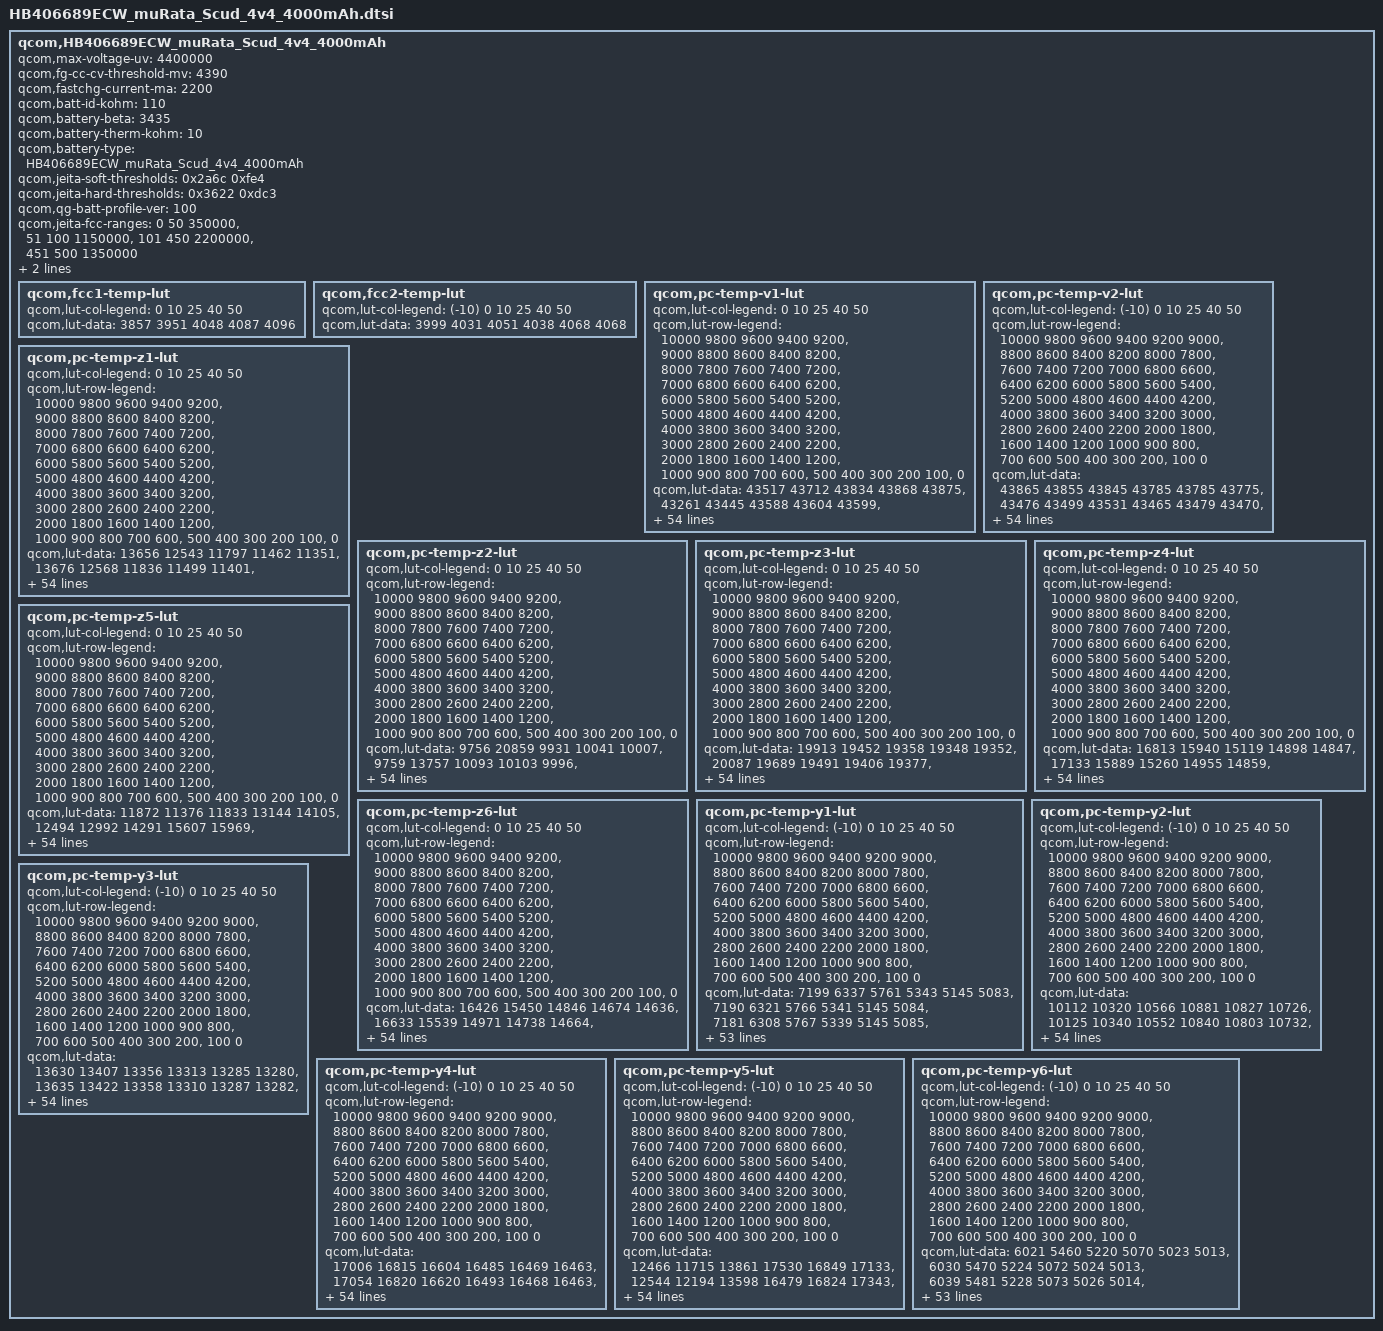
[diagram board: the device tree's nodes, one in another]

qcom,HB406689ECW_muRata_Scud_4v4_4000mAh {
    /* 3463304_Huawei_BangkokScud_4000mAh_averaged_MasterSlave_Jul12th2018 */
    qcom,max-voltage-uv = <4400000>;
    qcom,fg-cc-cv-threshold-mv = <4390>;
    qcom,fastchg-current-ma = <2200>;
    qcom,batt-id-kohm = <110>;
    qcom,battery-beta = <3435>;
    qcom,battery-therm-kohm = <10>;
    qcom,battery-type = "HB406689ECW_muRata_Scud_4v4_4000mAh";
    qcom,jeita-soft-thresholds = <0x2a6c 0xfe4>;
    qcom,jeita-hard-thresholds = <0x3622 0xdc3>;
    qcom,qg-batt-profile-ver = <100>;
    qcom,jeita-fcc-ranges = <0   50  350000>,
                            <51  100  1150000>,
			    <101  450  2200000>,
			    <451  500  1350000>;
	qcom,jeita-fv-ranges = <0   450  4400000>,
				<451 500  4100000>;

	qcom,fcc1-temp-lut {
		qcom,lut-col-legend = <0 10 25 40 50>;
		qcom,lut-data = <3857 3951 4048 4087 4096>;
	};

	qcom,fcc2-temp-lut {
		qcom,lut-col-legend = <(-10) 0 10 25 40 50>;
		qcom,lut-data = <3999 4031 4051 4038 4068 4068>;
	};

	qcom,pc-temp-v1-lut {
		qcom,lut-col-legend = <0 10 25 40 50>;
		qcom,lut-row-legend = <10000 9800 9600 9400 9200>,
			<9000 8800 8600 8400 8200>,
			<8000 7800 7600 7400 7200>,
			<7000 6800 6600 6400 6200>,
			<6000 5800 5600 5400 5200>,
			<5000 4800 4600 4400 4200>,
			<4000 3800 3600 3400 3200>,
			<3000 2800 2600 2400 2200>,
			<2000 1800 1600 1400 1200>,
			<1000 900 800 700 600>,
			<500 400 300 200 100>,
			<0>;
		qcom,lut-data = <43517 43712 43834 43868 43875>,
			<43261 43445 43588 43604 43599>,
			<43008 43186 43334 43355 43344>,
			<42759 42934 43079 43107 43099>,
			<42515 42689 42831 42860 42855>,
			<42275 42445 42586 42613 42614>,
			<42041 42204 42343 42368 42376>,
			<41811 41967 42101 42127 42137>,
			<41587 41738 41863 41888 41899>,
			<41369 41514 41629 41655 41664>,
			<41157 41296 41400 41427 41434>,
			<40951 41082 41180 41204 41209>,
			<40753 40874 40965 40986 40990>,
			<40564 40676 40759 40775 40779>,
			<40381 40485 40559 40571 40576>,
			<40204 40303 40367 40376 40382>,
			<40035 40132 40186 40191 40197>,
			<39873 39967 40014 40018 40019>,
			<39718 39806 39847 39851 39848>,
			<39570 39650 39693 39692 39687>,
			<39427 39492 39535 39536 39532>,
			<39289 39335 39338 39355 39355>,
			<39161 39179 39094 39118 39131>,
			<39038 39018 38894 38904 38919>,
			<38922 38855 38752 38763 38769>,
			<38810 38708 38637 38650 38647>,
			<38704 38571 38540 38542 38534>,
			<38607 38457 38459 38439 38431>,
			<38515 38379 38383 38346 38337>,
			<38433 38317 38309 38262 38251>,
			<38367 38265 38241 38187 38172>,
			<38309 38218 38178 38117 38101>,
			<38258 38176 38122 38054 38036>,
			<38216 38135 38069 37996 37975>,
			<38177 38096 38022 37947 37919>,
			<38135 38056 37977 37900 37864>,
			<38090 38017 37931 37847 37801>,
			<38042 37973 37884 37791 37735>,
			<37991 37907 37820 37721 37656>,
			<37934 37811 37723 37626 37560>,
			<37849 37701 37608 37513 37450>,
			<37703 37575 37486 37391 37328>,
			<37536 37429 37348 37252 37189>,
			<37353 37246 37172 37083 37019>,
			<37166 37097 37003 36920 36860>,
			<37019 36974 36879 36799 36743>,
			<36958 36920 36835 36756 36697>,
			<36896 36870 36786 36710 36649>,
			<36814 36805 36720 36640 36574>,
			<36639 36658 36540 36418 36337>,
			<36236 36296 36161 36032 35949>,
			<35698 35805 35668 35540 35457>,
			<34998 35169 35040 34912 34834>,
			<34001 34313 34194 34066 33987>,
			<32357 32982 32888 32746 32668>,
			<30000 30000 30000 30000 30000>;
	};

	qcom,pc-temp-v2-lut {
		qcom,lut-col-legend = <(-10) 0 10 25 40 50>;
		qcom,lut-row-legend = <10000 9800 9600 9400 9200 9000>,
			<8800 8600 8400 8200 8000 7800>,
			<7600 7400 7200 7000 6800 6600>,
			<6400 6200 6000 5800 5600 5400>,
			<5200 5000 4800 4600 4400 4200>,
			<4000 3800 3600 3400 3200 3000>,
			<2800 2600 2400 2200 2000 1800>,
			<1600 1400 1200 1000 900 800>,
			<700 600 500 400 300 200>,
			<100 0>;
		qcom,lut-data = <43865 43855 43845 43785 43785 43775>,
			<43476 43499 43531 43465 43479 43470>,
			<43121 43176 43238 43168 43191 43183>,
			<42806 42889 42966 42896 42926 42919>,
			<42527 42637 42717 42649 42682 42675>,
			<42259 42392 42473 42408 42442 42435>,
			<41994 42146 42227 42167 42199 42194>,
			<41734 41903 41985 41928 41960 41956>,
			<41476 41659 41749 41694 41725 41721>,
			<41219 41415 41518 41462 41495 41489>,
			<40970 41170 41291 41235 41268 41262>,
			<40733 40922 41069 41013 41046 41040>,
			<40504 40676 40848 40797 40828 40822>,
			<40272 40437 40620 40591 40620 40615>,
			<40039 40204 40388 40393 40417 40414>,
			<39816 39982 40159 40202 40223 40220>,
			<39613 39773 39930 40024 40036 40034>,
			<39420 39574 39710 39845 39855 39854>,
			<39234 39386 39507 39646 39676 39682>,
			<39055 39206 39314 39432 39500 39514>,
			<38887 39036 39135 39228 39309 39328>,
			<38729 38873 38968 39034 39090 39107>,
			<38581 38721 38814 38856 38886 38899>,
			<38439 38581 38674 38702 38725 38734>,
			<38303 38453 38546 38565 38587 38591>,
			<38178 38331 38426 38445 38464 38466>,
			<38065 38212 38315 38340 38356 38356>,
			<37961 38102 38211 38245 38259 38257>,
			<37868 38002 38115 38154 38170 38165>,
			<37784 37909 38024 38068 38089 38080>,
			<37705 37830 37942 37992 38016 38005>,
			<37628 37763 37865 37923 37949 37938>,
			<37553 37705 37796 37860 37882 37870>,
			<37478 37649 37737 37803 37816 37803>,
			<37403 37599 37684 37750 37747 37732>,
			<37327 37546 37633 37687 37661 37636>,
			<37252 37490 37584 37612 37559 37512>,
			<37175 37430 37529 37531 37460 37401>,
			<37098 37367 37458 37448 37375 37315>,
			<37021 37298 37374 37362 37291 37234>,
			<36941 37203 37276 37264 37199 37145>,
			<36856 37053 37156 37152 37099 37049>,
			<36764 36883 37017 37024 36975 36926>,
			<36662 36698 36850 36874 36830 36783>,
			<36535 36552 36656 36713 36694 36650>,
			<36376 36399 36516 36617 36620 36574>,
			<36267 36317 36454 36572 36576 36531>,
			<36146 36230 36390 36516 36511 36468>,
			<35993 36117 36300 36426 36386 36341>,
			<35783 35927 36131 36225 36088 36041>,
			<35457 35533 35770 35820 35626 35582>,
			<34913 34925 35206 35276 35042 35002>,
			<34065 34128 34462 34589 34284 34252>,
			<32953 32886 33489 33660 33238 33230>,
			<31547 31082 31993 32192 31519 31589>,
			<29383 26587 28489 28493 26939 26874>;
	};

	qcom,pc-temp-z1-lut {
		qcom,lut-col-legend = <0 10 25 40 50>;
		qcom,lut-row-legend = <10000 9800 9600 9400 9200>,
			<9000 8800 8600 8400 8200>,
			<8000 7800 7600 7400 7200>,
			<7000 6800 6600 6400 6200>,
			<6000 5800 5600 5400 5200>,
			<5000 4800 4600 4400 4200>,
			<4000 3800 3600 3400 3200>,
			<3000 2800 2600 2400 2200>,
			<2000 1800 1600 1400 1200>,
			<1000 900 800 700 600>,
			<500 400 300 200 100>,
			<0>;
		qcom,lut-data = <13656 12543 11797 11462 11351>,
			<13676 12568 11836 11499 11401>,
			<13687 12585 11842 11504 11406>,
			<13699 12596 11844 11507 11408>,
			<13701 12605 11842 11507 11409>,
			<13707 12602 11837 11507 11410>,
			<13709 12592 11834 11507 11411>,
			<13692 12584 11832 11508 11412>,
			<13667 12582 11831 11509 11415>,
			<13661 12578 11832 11510 11416>,
			<13668 12576 11835 11511 11417>,
			<13672 12576 11837 11513 11418>,
			<13650 12575 11840 11514 11420>,
			<13610 12567 11843 11516 11422>,
			<13587 12556 11845 11519 11424>,
			<13576 12555 11849 11521 11427>,
			<13569 12565 11852 11524 11430>,
			<13564 12573 11857 11527 11433>,
			<13562 12574 11862 11531 11436>,
			<13559 12575 11870 11534 11439>,
			<13547 12577 11877 11538 11441>,
			<13530 12580 11881 11542 11444>,
			<13520 12584 11883 11547 11447>,
			<13512 12590 11885 11552 11451>,
			<13504 12596 11891 11556 11454>,
			<13496 12600 11897 11559 11459>,
			<13488 12602 11905 11564 11463>,
			<13482 12603 11913 11571 11468>,
			<13476 12604 11919 11578 11472>,
			<13472 12606 11923 11583 11477>,
			<13473 12608 11927 11587 11481>,
			<13477 12613 11932 11592 11485>,
			<13481 12618 11938 11598 11489>,
			<13492 12622 11944 11603 11493>,
			<13505 12627 11951 11610 11498>,
			<13510 12633 11958 11616 11502>,
			<13513 12640 11966 11622 11507>,
			<13519 12650 11975 11627 11511>,
			<13539 12661 11983 11632 11516>,
			<13574 12674 11993 11637 11521>,
			<13605 12688 12003 11643 11526>,
			<13640 12701 12013 11649 11530>,
			<13659 12717 12024 11656 11534>,
			<13668 12750 12036 11664 11538>,
			<13673 12754 12056 11674 11544>,
			<13673 12763 12061 11681 11550>,
			<13666 12783 12063 11682 11551>,
			<13658 12745 12066 11688 11554>,
			<13667 12744 12070 11696 11561>,
			<13711 12765 12086 11707 11567>,
			<13725 12796 12088 11717 11575>,
			<13715 12824 12115 11725 11585>,
			<13735 12831 12126 11740 11598>,
			<13790 12854 12160 11759 11616>,
			<13790 12854 12160 11759 11616>,
			<13790 12854 12160 11759 11616>;
	};

	qcom,pc-temp-z2-lut {
		qcom,lut-col-legend = <0 10 25 40 50>;
		qcom,lut-row-legend = <10000 9800 9600 9400 9200>,
			<9000 8800 8600 8400 8200>,
			<8000 7800 7600 7400 7200>,
			<7000 6800 6600 6400 6200>,
			<6000 5800 5600 5400 5200>,
			<5000 4800 4600 4400 4200>,
			<4000 3800 3600 3400 3200>,
			<3000 2800 2600 2400 2200>,
			<2000 1800 1600 1400 1200>,
			<1000 900 800 700 600>,
			<500 400 300 200 100>,
			<0>;
		qcom,lut-data = <9756 20859 9931 10041 10007>,
			<9759 13757 10093 10103 9996>,
			<9793 9989 10151 10193 10054>,
			<9834 9931 10173 10244 10136>,
			<9851 9930 10164 10252 10150>,
			<9859 9929 10143 10241 10064>,
			<9867 9930 10131 10233 9994>,
			<9874 9932 10121 10235 10003>,
			<9881 9934 10116 10238 10021>,
			<9888 9936 10122 10229 10025>,
			<9897 9938 10134 10201 10021>,
			<9905 9940 10136 10187 10019>,
			<9913 9942 10131 10197 10032>,
			<9921 9941 10129 10210 10048>,
			<9928 9939 10133 10212 10050>,
			<9935 9939 10141 10208 10048>,
			<9939 9943 10149 10198 10047>,
			<9941 9949 10157 10139 10057>,
			<9940 9955 10165 10081 10070>,
			<9940 9964 10172 10076 10079>,
			<9940 9976 10180 10075 10087>,
			<9940 9993 10208 10086 10095>,
			<9941 10013 10280 10205 10109>,
			<9947 10033 10314 10304 10121>,
			<9955 10056 10268 10252 10125>,
			<9964 10072 10212 10147 10129>,
			<9975 10083 10209 10137 10124>,
			<9986 10090 10218 10235 10093>,
			<9998 10089 10222 10302 10061>,
			<10009 10085 10220 10276 10042>,
			<10013 10081 10217 10230 10027>,
			<10017 10075 10208 10202 10018>,
			<10018 10070 10192 10178 10010>,
			<10017 10069 10179 10159 10007>,
			<10016 10067 10168 10130 10018>,
			<10017 10067 10160 10102 10039>,
			<10021 10067 10157 10101 10062>,
			<10024 10068 10156 10115 10094>,
			<9871 10070 10157 10120 10115>,
			<9596 10078 10174 10120 10129>,
			<9512 10086 10190 10120 10138>,
			<9509 10090 10188 10122 10132>,
			<9505 10097 10184 10126 10117>,
			<9491 10115 10191 10144 10109>,
			<9550 10032 10225 10159 10109>,
			<9553 9967 10257 10157 10132>,
			<9525 9960 10247 10160 10119>,
			<9505 9958 10242 10162 10132>,
			<9494 9950 10242 10195 10167>,
			<9468 9940 10312 10173 10097>,
			<9475 9927 10273 10113 10010>,
			<9423 9863 10233 10047 9972>,
			<9360 9783 10201 10012 9935>,
			<9300 9664 10143 9963 9876>,
			<9300 9664 10143 9963 9876>,
			<9300 9664 10143 9963 9876>;
	};

	qcom,pc-temp-z3-lut {
		qcom,lut-col-legend = <0 10 25 40 50>;
		qcom,lut-row-legend = <10000 9800 9600 9400 9200>,
			<9000 8800 8600 8400 8200>,
			<8000 7800 7600 7400 7200>,
			<7000 6800 6600 6400 6200>,
			<6000 5800 5600 5400 5200>,
			<5000 4800 4600 4400 4200>,
			<4000 3800 3600 3400 3200>,
			<3000 2800 2600 2400 2200>,
			<2000 1800 1600 1400 1200>,
			<1000 900 800 700 600>,
			<500 400 300 200 100>,
			<0>;
		qcom,lut-data = <19913 19452 19358 19348 19352>,
			<20087 19689 19491 19406 19377>,
			<20148 19819 19537 19422 19398>,
			<20178 19850 19560 19433 19406>,
			<20177 19867 19562 19440 19408>,
			<20158 19875 19563 19447 19406>,
			<20138 19880 19563 19449 19404>,
			<20122 19882 19561 19447 19401>,
			<20108 19876 19558 19441 19398>,
			<20097 19863 19553 19435 19396>,
			<20088 19855 19544 19426 19394>,
			<20080 19851 19536 19421 19393>,
			<20070 19847 19528 19418 19391>,
			<20061 19842 19521 19417 19389>,
			<20060 19835 19518 19415 19386>,
			<20081 19824 19516 19413 19382>,
			<20113 19801 19513 19409 19379>,
			<20140 19780 19509 19402 19377>,
			<20167 19769 19505 19395 19376>,
			<20188 19760 19501 19392 19373>,
			<20202 19758 19498 19391 19371>,
			<20212 19761 19505 19392 19370>,
			<20213 19764 19531 19403 19374>,
			<20208 19772 19545 19412 19377>,
			<20202 19790 19533 19404 19378>,
			<20198 19799 19515 19389 19378>,
			<20194 19803 19507 19388 19381>,
			<20189 19805 19501 19405 19391>,
			<20180 19802 19499 19419 19398>,
			<20169 19792 19504 19422 19397>,
			<20158 19783 19512 19424 19395>,
			<20146 19775 19517 19424 19393>,
			<20134 19768 19521 19422 19389>,
			<20120 19764 19523 19419 19384>,
			<20106 19762 19522 19413 19378>,
			<20091 19759 19520 19406 19373>,
			<20078 19753 19516 19400 19369>,
			<20055 19745 19509 19395 19366>,
			<19876 19739 19503 19391 19365>,
			<19580 19732 19499 19389 19365>,
			<19478 19725 19496 19387 19365>,
			<19467 19719 19492 19388 19365>,
			<19449 19709 19489 19389 19365>,
			<19414 19690 19485 19386 19367>,
			<19404 19498 19472 19380 19365>,
			<19400 19371 19456 19378 19353>,
			<19392 19360 19445 19372 19351>,
			<19389 19337 19446 19369 19350>,
			<19389 19334 19450 19368 19348>,
			<19392 19349 19439 19386 19366>,
			<19417 19369 19468 19401 19376>,
			<19444 19369 19480 19404 19379>,
			<19471 19393 19489 19409 19382>,
			<19514 19399 19497 19414 19392>,
			<19514 19399 19497 19414 19392>,
			<19514 19399 19497 19414 19392>;
	};

	qcom,pc-temp-z4-lut {
		qcom,lut-col-legend = <0 10 25 40 50>;
		qcom,lut-row-legend = <10000 9800 9600 9400 9200>,
			<9000 8800 8600 8400 8200>,
			<8000 7800 7600 7400 7200>,
			<7000 6800 6600 6400 6200>,
			<6000 5800 5600 5400 5200>,
			<5000 4800 4600 4400 4200>,
			<4000 3800 3600 3400 3200>,
			<3000 2800 2600 2400 2200>,
			<2000 1800 1600 1400 1200>,
			<1000 900 800 700 600>,
			<500 400 300 200 100>,
			<0>;
		qcom,lut-data = <16813 15940 15119 14898 14847>,
			<17133 15889 15260 14955 14859>,
			<16952 15808 15187 14943 14867>,
			<16686 15672 15098 14894 14838>,
			<16496 15512 15037 14857 14815>,
			<16330 15398 14984 14829 14797>,
			<16189 15309 14942 14805 14781>,
			<16071 15237 14908 14781 14765>,
			<15971 15180 14880 14763 14750>,
			<15889 15134 14851 14758 14743>,
			<15820 15090 14827 14757 14739>,
			<15761 15048 14816 14755 14736>,
			<15710 15009 14811 14750 14732>,
			<15665 14972 14806 14744 14728>,
			<15611 14939 14798 14738 14724>,
			<15539 14918 14787 14733 14720>,
			<15460 14904 14778 14729 14716>,
			<15384 14893 14769 14727 14711>,
			<15306 14882 14761 14725 14705>,
			<15241 14872 14751 14720 14700>,
			<15191 14862 14743 14714 14696>,
			<15150 14851 14749 14716 14699>,
			<15118 14845 14782 14759 14744>,
			<15093 14847 14813 14801 14786>,
			<15072 14855 14839 14811 14786>,
			<15052 14867 14858 14817 14780>,
			<15035 14887 14858 14814 14770>,
			<15023 14903 14851 14785 14749>,
			<15016 14904 14841 14756 14730>,
			<15011 14902 14824 14740 14719>,
			<15005 14899 14805 14726 14710>,
			<15001 14891 14788 14716 14702>,
			<14995 14881 14771 14708 14694>,
			<14988 14869 14757 14703 14688>,
			<14977 14856 14747 14699 14685>,
			<14963 14841 14739 14698 14682>,
			<14941 14826 14735 14697 14682>,
			<14928 14812 14733 14698 14684>,
			<15085 14804 14733 14700 14685>,
			<15368 14798 14739 14706 14688>,
			<15448 14791 14745 14712 14689>,
			<15423 14778 14738 14707 14685>,
			<15393 14767 14725 14696 14678>,
			<15363 14762 14721 14699 14679>,
			<15186 14875 14708 14695 14677>,
			<15148 14965 14683 14670 14664>,
			<15152 14971 14682 14665 14656>,
			<15152 14988 14670 14655 14643>,
			<15141 14982 14664 14653 14642>,
			<15136 14968 14693 14663 14657>,
			<15140 14975 14684 14667 14665>,
			<15166 14997 14685 14672 14671>,
			<15180 14995 14687 14677 14675>,
			<15231 15027 14696 14682 14673>,
			<15231 15027 14696 14682 14673>,
			<15231 15027 14696 14682 14673>;
	};

	qcom,pc-temp-z5-lut {
		qcom,lut-col-legend = <0 10 25 40 50>;
		qcom,lut-row-legend = <10000 9800 9600 9400 9200>,
			<9000 8800 8600 8400 8200>,
			<8000 7800 7600 7400 7200>,
			<7000 6800 6600 6400 6200>,
			<6000 5800 5600 5400 5200>,
			<5000 4800 4600 4400 4200>,
			<4000 3800 3600 3400 3200>,
			<3000 2800 2600 2400 2200>,
			<2000 1800 1600 1400 1200>,
			<1000 900 800 700 600>,
			<500 400 300 200 100>,
			<0>;
		qcom,lut-data = <11872 11376 11833 13144 14105>,
			<12494 12992 14291 15607 15969>,
			<12869 14013 15640 16548 17892>,
			<13142 14463 16511 17468 18954>,
			<13329 14765 16807 18293 19191>,
			<13466 15083 16986 19038 19097>,
			<13578 15424 17211 19660 19019>,
			<13677 15705 17485 20250 19262>,
			<13761 15872 17815 20701 19751>,
			<13826 16021 18386 20579 20022>,
			<13879 16252 18998 19779 20163>,
			<13921 16688 19087 19353 20308>,
			<13942 17243 18912 19586 20566>,
			<13954 17973 18800 19940 20811>,
			<14013 18763 19108 20227 20781>,
			<14340 19091 19733 20594 20530>,
			<14869 19189 20291 20712 20412>,
			<15495 19303 20846 20214 20852>,
			<16351 19588 21467 19707 21542>,
			<17321 20183 22048 19848 22136>,
			<18428 21067 22856 20455 22729>,
			<19647 22669 27256 21500 22904>,
			<20819 24775 40314 24345 22719>,
			<21937 28165 46667 26445 22366>,
			<23163 33124 39329 23795 21020>,
			<24757 35589 29232 18657 18744>,
			<26552 36427 25145 17653 18336>,
			<27973 36780 22625 19146 19857>,
			<29261 35596 21860 20833 21467>,
			<30071 32433 22126 22034 22529>,
			<29974 29876 22638 23193 23505>,
			<29411 27898 23504 24556 24191>,
			<28783 26623 25060 26173 25148>,
			<27842 26549 26659 27079 25679>,
			<26750 26618 28599 27021 25823>,
			<26064 26678 29934 26679 25935>,
			<25625 26731 29730 26185 25871>,
			<24940 26820 28900 24870 25509>,
			<20491 27264 27963 23687 24960>,
			<13556 28465 26741 22125 23478>,
			<11590 29061 25656 20924 22055>,
			<11609 28674 25073 21151 21999>,
			<11603 27973 24658 21668 22377>,
			<11474 26962 24253 20329 22397>,
			<11827 17738 24517 19831 21764>,
			<11844 12117 25905 22136 20109>,
			<11722 11921 23006 21316 21078>,
			<11659 11589 24586 22516 24793>,
			<11661 11577 27491 22990 25121>,
			<11755 11877 21490 25058 26305>,
			<12010 12140 25515 25929 25045>,
			<12009 11967 26778 24313 23303>,
			<12038 12183 27080 23684 21716>,
			<12005 12005 25149 22276 22202>,
			<12005 12005 25149 22276 22202>,
			<12005 12005 25149 22276 22202>;
	};

	qcom,pc-temp-z6-lut {
		qcom,lut-col-legend = <0 10 25 40 50>;
		qcom,lut-row-legend = <10000 9800 9600 9400 9200>,
			<9000 8800 8600 8400 8200>,
			<8000 7800 7600 7400 7200>,
			<7000 6800 6600 6400 6200>,
			<6000 5800 5600 5400 5200>,
			<5000 4800 4600 4400 4200>,
			<4000 3800 3600 3400 3200>,
			<3000 2800 2600 2400 2200>,
			<2000 1800 1600 1400 1200>,
			<1000 900 800 700 600>,
			<500 400 300 200 100>,
			<0>;
		qcom,lut-data = <16426 15450 14846 14674 14636>,
			<16633 15539 14971 14738 14664>,
			<16572 15572 14961 14737 14675>,
			<16475 15532 14945 14726 14670>,
			<16390 15463 14925 14716 14663>,
			<16303 15415 14900 14707 14655>,
			<16227 15378 14879 14698 14647>,
			<16165 15345 14864 14687 14639>,
			<16113 15315 14850 14677 14632>,
			<16071 15289 14834 14670 14627>,
			<16038 15265 14820 14666 14625>,
			<16009 15245 14811 14662 14622>,
			<15982 15226 14805 14659 14620>,
			<15959 15208 14799 14655 14617>,
			<15938 15191 14794 14652 14614>,
			<15920 15175 14790 14649 14610>,
			<15902 15159 14785 14645 14607>,
			<15883 15146 14780 14641 14604>,
			<15863 15137 14775 14636 14601>,
			<15846 15131 14769 14633 14598>,
			<15833 15128 14765 14630 14595>,
			<15821 15128 14772 14632 14596>,
			<15809 15127 14803 14658 14618>,
			<15795 15132 14822 14681 14638>,
			<15783 15148 14826 14680 14638>,
			<15772 15162 14828 14677 14637>,
			<15762 15175 14827 14675 14636>,
			<15753 15184 14822 14672 14633>,
			<15744 15183 14817 14670 14629>,
			<15736 15178 14814 14666 14625>,
			<15729 15173 14811 14662 14620>,
			<15723 15168 14808 14658 14616>,
			<15716 15162 14804 14654 14611>,
			<15708 15156 14801 14651 14607>,
			<15699 15152 14798 14647 14602>,
			<15690 15146 14796 14643 14599>,
			<15679 15139 14793 14641 14598>,
			<15666 15132 14791 14639 14598>,
			<15649 15132 14790 14639 14597>,
			<15630 15132 14794 14641 14599>,
			<15622 15132 14797 14643 14600>,
			<15621 15131 14794 14642 14599>,
			<15617 15129 14791 14640 14596>,
			<15598 15125 14791 14640 14598>,
			<15513 15084 14784 14637 14597>,
			<15497 15062 14769 14627 14586>,
			<15498 15059 14764 14622 14582>,
			<15499 15058 14762 14616 14576>,
			<15502 15059 14763 14616 14575>,
			<15515 15067 14773 14631 14592>,
			<15541 15089 14790 14643 14603>,
			<15577 15111 14802 14650 14609>,
			<15616 15135 14815 14658 14616>,
			<15687 15173 14835 14669 14625>,
			<15687 15173 14835 14669 14625>,
			<15687 15173 14835 14669 14625>;
	};

	qcom,pc-temp-y1-lut {
		qcom,lut-col-legend = <(-10) 0 10 25 40 50>;
		qcom,lut-row-legend = <10000 9800 9600 9400 9200 9000>,
			<8800 8600 8400 8200 8000 7800>,
			<7600 7400 7200 7000 6800 6600>,
			<6400 6200 6000 5800 5600 5400>,
			<5200 5000 4800 4600 4400 4200>,
			<4000 3800 3600 3400 3200 3000>,
			<2800 2600 2400 2200 2000 1800>,
			<1600 1400 1200 1000 900 800>,
			<700 600 500 400 300 200>,
			<100 0>;
		qcom,lut-data = <7199 6337 5761 5343 5145 5083>,
			<7190 6321 5766 5341 5145 5084>,
			<7181 6308 5767 5339 5145 5085>,
			<7172 6300 5766 5337 5145 5086>,
			<7163 6296 5765 5336 5145 5087>,
			<7157 6296 5764 5336 5145 5087>,
			<7150 6304 5761 5336 5145 5088>,
			<7145 6314 5757 5337 5146 5088>,
			<7150 6315 5759 5337 5146 5089>,
			<7176 6312 5767 5338 5146 5089>,
			<7196 6310 5771 5339 5147 5090>,
			<7196 6307 5767 5341 5148 5091>,
			<7188 6305 5762 5343 5149 5091>,
			<7187 6310 5764 5345 5151 5093>,
			<7187 6321 5775 5347 5153 5094>,
			<7187 6327 5779 5349 5154 5096>,
			<7188 6328 5775 5353 5156 5097>,
			<7189 6329 5770 5357 5158 5099>,
			<7188 6327 5773 5361 5160 5100>,
			<7180 6319 5783 5364 5163 5102>,
			<7170 6316 5787 5368 5166 5104>,
			<7152 6319 5785 5373 5169 5107>,
			<7130 6322 5783 5379 5172 5109>,
			<7126 6322 5785 5384 5175 5111>,
			<7131 6320 5792 5389 5178 5112>,
			<7137 6319 5795 5394 5182 5114>,
			<7138 6323 5795 5400 5185 5118>,
			<7139 6328 5794 5406 5188 5122>,
			<7148 6325 5795 5410 5192 5124>,
			<7175 6318 5796 5414 5196 5127>,
			<7192 6315 5798 5418 5199 5129>,
			<7178 6321 5804 5423 5202 5132>,
			<7157 6328 5809 5427 5205 5134>,
			<7151 6326 5810 5428 5208 5137>,
			<7150 6321 5810 5429 5212 5139>,
			<7148 6316 5811 5430 5215 5141>,
			<7137 6311 5811 5431 5217 5142>,
			<7120 6307 5814 5434 5218 5143>,
			<7115 6302 5819 5439 5219 5144>,
			<7110 6295 5824 5446 5220 5145>,
			<7106 6296 5823 5447 5222 5147>,
			<7102 6318 5813 5446 5226 5149>,
			<7098 6330 5812 5448 5228 5151>,
			<7106 6334 5820 5458 5230 5153>,
			<7123 6347 5847 5468 5236 5158>,
			<7213 6383 5846 5470 5242 5162>,
			<7231 6381 5844 5472 5243 5164>,
			<7228 6357 5852 5477 5247 5166>,
			<7237 6377 5854 5488 5249 5167>,
			<7369 6371 5856 5487 5253 5170>,
			<7474 6398 5857 5489 5261 5178>,
			<7616 6423 5866 5503 5270 5184>,
			<7857 6514 5885 5529 5282 5193>,
			<7969 6656 5925 5532 5298 5207>,
			<7969 6656 5925 5532 5298 5207>,
			<7969 6656 5925 5532 5298 5207>;
	};

	qcom,pc-temp-y2-lut {
		qcom,lut-col-legend = <(-10) 0 10 25 40 50>;
		qcom,lut-row-legend = <10000 9800 9600 9400 9200 9000>,
			<8800 8600 8400 8200 8000 7800>,
			<7600 7400 7200 7000 6800 6600>,
			<6400 6200 6000 5800 5600 5400>,
			<5200 5000 4800 4600 4400 4200>,
			<4000 3800 3600 3400 3200 3000>,
			<2800 2600 2400 2200 2000 1800>,
			<1600 1400 1200 1000 900 800>,
			<700 600 500 400 300 200>,
			<100 0>;
		qcom,lut-data = <10112 10320 10566 10881 10827 10726>,
			<10125 10340 10552 10840 10803 10732>,
			<10140 10363 10547 10813 10769 10732>,
			<10155 10387 10547 10798 10734 10726>,
			<10172 10409 10553 10791 10707 10717>,
			<10189 10426 10561 10792 10697 10707>,
			<10207 10438 10574 10809 10699 10688>,
			<10226 10450 10591 10829 10704 10670>,
			<10245 10462 10605 10821 10728 10675>,
			<10262 10473 10617 10773 10798 10698>,
			<10280 10482 10631 10747 10840 10709>,
			<10297 10491 10646 10800 10849 10705>,
			<10313 10499 10661 10876 10858 10698>,
			<10321 10502 10672 10903 10878 10694>,
			<10325 10504 10681 10917 10914 10696>,
			<10329 10506 10684 10933 10946 10705>,
			<10335 10511 10678 10964 10973 10739>,
			<10341 10517 10673 10991 11003 10796>,
			<10340 10522 10670 10982 11050 10916>,
			<10325 10528 10665 10940 11109 11092>,
			<10306 10530 10662 10902 11110 11131>,
			<10292 10530 10662 10874 10948 10997>,
			<10275 10530 10662 10850 10807 10868>,
			<10193 10531 10662 10833 10794 10836>,
			<9898 10534 10662 10817 10788 10818>,
			<9706 10535 10664 10813 10786 10807>,
			<9697 10524 10670 10824 10785 10801>,
			<9693 10506 10676 10837 10788 10802>,
			<9690 10493 10683 10840 10802 10839>,
			<9688 10480 10689 10843 10825 10893>,
			<9685 10471 10690 10847 10843 10898>,
			<9683 10466 10683 10853 10857 10868>,
			<9680 10462 10676 10859 10861 10847>,
			<9677 10454 10672 10868 10871 10843>,
			<9675 10444 10669 10883 10885 10840>,
			<9673 10432 10667 10885 10871 10838>,
			<9671 10417 10666 10869 10828 10829>,
			<9669 10399 10665 10855 10806 10823>,
			<9667 10383 10657 10854 10808 10812>,
			<9665 10365 10641 10854 10815 10802>,
			<9664 10340 10623 10854 10840 10808>,
			<9663 10296 10599 10854 10885 10827>,
			<9662 10157 10571 10852 10866 10820>,
			<9661 9724 10536 10837 10822 10804>,
			<9659 9692 10491 10786 10805 10759>,
			<9658 9688 10450 10757 10781 10713>,
			<9657 9678 10427 10752 10784 10688>,
			<9656 9670 10402 10745 10776 10656>,
			<9655 9664 10366 10726 10761 10642>,
			<9652 9659 10319 10708 10703 10628>,
			<9651 9656 10246 10670 10687 10600>,
			<9651 9654 10020 10620 10648 10550>,
			<9649 9651 9689 10558 10594 10466>,
			<9648 9650 9660 10505 10581 10441>,
			<9648 9650 9660 10505 10581 10441>,
			<9648 9650 9660 10505 10581 10441>;
	};

	qcom,pc-temp-y3-lut {
		qcom,lut-col-legend = <(-10) 0 10 25 40 50>;
		qcom,lut-row-legend = <10000 9800 9600 9400 9200 9000>,
			<8800 8600 8400 8200 8000 7800>,
			<7600 7400 7200 7000 6800 6600>,
			<6400 6200 6000 5800 5600 5400>,
			<5200 5000 4800 4600 4400 4200>,
			<4000 3800 3600 3400 3200 3000>,
			<2800 2600 2400 2200 2000 1800>,
			<1600 1400 1200 1000 900 800>,
			<700 600 500 400 300 200>,
			<100 0>;
		qcom,lut-data = <13630 13407 13356 13313 13285 13280>,
			<13635 13422 13358 13310 13287 13282>,
			<13641 13437 13360 13308 13288 13283>,
			<13646 13451 13362 13308 13289 13284>,
			<13650 13463 13365 13309 13291 13285>,
			<13652 13473 13367 13311 13292 13286>,
			<13654 13482 13369 13314 13292 13287>,
			<13655 13488 13371 13318 13293 13288>,
			<13653 13491 13375 13318 13294 13289>,
			<13644 13492 13381 13315 13298 13289>,
			<13635 13493 13386 13313 13299 13289>,
			<13630 13490 13392 13313 13298 13289>,
			<13624 13484 13395 13313 13298 13289>,
			<13615 13478 13395 13313 13298 13290>,
			<13600 13473 13394 13317 13298 13291>,
			<13587 13468 13392 13320 13298 13292>,
			<13578 13464 13388 13323 13298 13292>,
			<13572 13461 13383 13326 13298 13292>,
			<13564 13458 13381 13325 13298 13293>,
			<13555 13454 13378 13322 13299 13294>,
			<13549 13451 13375 13320 13299 13294>,
			<13547 13446 13371 13317 13294 13289>,
			<13546 13441 13368 13315 13290 13285>,
			<13550 13439 13367 13312 13289 13284>,
			<13573 13438 13366 13309 13288 13283>,
			<13594 13437 13366 13309 13287 13283>,
			<13602 13435 13366 13310 13287 13283>,
			<13609 13434 13366 13312 13287 13283>,
			<13619 13432 13367 13312 13287 13282>,
			<13635 13432 13368 13312 13288 13282>,
			<13653 13433 13369 13312 13289 13281>,
			<13673 13438 13369 13313 13290 13282>,
			<13695 13445 13370 13314 13291 13283>,
			<13719 13453 13372 13316 13291 13284>,
			<13747 13461 13375 13317 13292 13286>,
			<13777 13469 13378 13318 13291 13285>,
			<13805 13475 13381 13317 13290 13283>,
			<13837 13482 13384 13316 13289 13282>,
			<13875 13493 13389 13316 13289 13283>,
			<13924 13508 13393 13316 13290 13285>,
			<13976 13516 13394 13316 13290 13286>,
			<14025 13520 13394 13317 13291 13286>,
			<14083 13529 13395 13317 13291 13286>,
			<14165 13563 13398 13317 13290 13285>,
			<14273 13603 13389 13316 13289 13284>,
			<14218 13587 13385 13317 13294 13287>,
			<14356 13644 13393 13320 13297 13290>,
			<14576 13726 13408 13325 13300 13292>,
			<14935 13846 13422 13328 13300 13291>,
			<15853 14053 13438 13331 13296 13289>,
			<17777 14393 13457 13332 13298 13290>,
			<22559 15238 13502 13336 13302 13292>,
			<35567 17748 13654 13347 13307 13297>,
			<64497 24759 14099 13364 13316 13306>,
			<64497 24759 14099 13364 13316 13306>,
			<64497 24759 14099 13364 13316 13306>;
	};

	qcom,pc-temp-y4-lut {
		qcom,lut-col-legend = <(-10) 0 10 25 40 50>;
		qcom,lut-row-legend = <10000 9800 9600 9400 9200 9000>,
			<8800 8600 8400 8200 8000 7800>,
			<7600 7400 7200 7000 6800 6600>,
			<6400 6200 6000 5800 5600 5400>,
			<5200 5000 4800 4600 4400 4200>,
			<4000 3800 3600 3400 3200 3000>,
			<2800 2600 2400 2200 2000 1800>,
			<1600 1400 1200 1000 900 800>,
			<700 600 500 400 300 200>,
			<100 0>;
		qcom,lut-data = <17006 16815 16604 16485 16469 16463>,
			<17054 16820 16620 16493 16468 16463>,
			<17102 16829 16635 16501 16468 16462>,
			<17144 16839 16649 16509 16469 16462>,
			<17174 16848 16661 16515 16471 16463>,
			<17185 16851 16673 16520 16474 16463>,
			<17177 16851 16683 16523 16479 16465>,
			<17163 16850 16692 16526 16483 16467>,
			<17153 16849 16698 16534 16485 16470>,
			<17146 16846 16702 16553 16486 16473>,
			<17138 16841 16705 16571 16489 16477>,
			<17125 16835 16707 16584 16496 16483>,
			<17109 16829 16709 16595 16507 16489>,
			<17095 16822 16706 16606 16517 16494>,
			<17082 16814 16694 16617 16526 16499>,
			<17069 16806 16680 16626 16538 16506>,
			<17052 16796 16663 16634 16556 16518>,
			<17034 16786 16645 16640 16571 16531>,
			<17019 16776 16631 16632 16576 16545>,
			<17007 16766 16618 16600 16579 16558>,
			<16994 16758 16610 16568 16576 16558>,
			<16971 16751 16604 16537 16535 16525>,
			<16948 16744 16601 16512 16495 16490>,
			<16948 16737 16600 16506 16481 16475>,
			<16968 16729 16599 16503 16472 16465>,
			<16984 16721 16599 16502 16470 16462>,
			<16990 16710 16599 16503 16472 16462>,
			<16993 16703 16599 16505 16475 16462>,
			<17000 16703 16598 16508 16479 16465>,
			<17013 16706 16596 16515 16486 16472>,
			<17027 16711 16596 16521 16493 16480>,
			<17043 16721 16598 16528 16502 16488>,
			<17062 16737 16601 16536 16508 16495>,
			<17081 16756 16607 16543 16511 16499>,
			<17102 16781 16620 16551 16513 16502>,
			<17125 16806 16634 16552 16508 16497>,
			<17153 16832 16653 16544 16491 16476>,
			<17184 16857 16669 16537 16482 16466>,
			<17219 16878 16680 16534 16484 16469>,
			<17260 16897 16688 16532 16486 16474>,
			<17300 16899 16695 16532 16489 16479>,
			<17340 16874 16700 16534 16493 16484>,
			<17368 16873 16696 16533 16491 16482>,
			<17378 16931 16675 16527 16482 16472>,
			<17358 16933 16632 16507 16465 16455>,
			<17106 16868 16614 16504 16473 16469>,
			<17119 16908 16637 16515 16484 16484>,
			<17149 16959 16672 16531 16501 16503>,
			<17217 17018 16718 16550 16505 16505>,
			<17551 17077 16757 16546 16485 16479>,
			<18237 17075 16773 16526 16478 16471>,
			<20007 17247 16832 16538 16483 16476>,
			<25968 18243 16956 16569 16499 16484>,
			<48995 21935 17124 16626 16552 16530>,
			<48995 21935 17124 16626 16552 16530>,
			<48995 21935 17124 16626 16552 16530>;
	};

	qcom,pc-temp-y5-lut {
		qcom,lut-col-legend = <(-10) 0 10 25 40 50>;
		qcom,lut-row-legend = <10000 9800 9600 9400 9200 9000>,
			<8800 8600 8400 8200 8000 7800>,
			<7600 7400 7200 7000 6800 6600>,
			<6400 6200 6000 5800 5600 5400>,
			<5200 5000 4800 4600 4400 4200>,
			<4000 3800 3600 3400 3200 3000>,
			<2800 2600 2400 2200 2000 1800>,
			<1600 1400 1200 1000 900 800>,
			<700 600 500 400 300 200>,
			<100 0>;
		qcom,lut-data = <12466 11715 13861 17530 16849 17133>,
			<12544 12194 13598 16479 16824 17343>,
			<12677 12717 13449 15635 16717 17431>,
			<12855 13281 13386 15014 16544 17426>,
			<13072 13880 13381 14634 16319 17358>,
			<13320 14512 13408 14512 16057 17255>,
			<13669 15227 13540 14784 15640 17048>,
			<14015 15939 13809 15164 15273 16755>,
			<14138 16524 14257 15018 15434 16459>,
			<14182 17072 15132 14158 16163 16129>,
			<14239 17299 16165 13690 16487 15760>,
			<14523 17184 17490 13697 15840 15227>,
			<14896 16991 18797 13714 15090 14814>,
			<14915 16840 19619 13908 14973 14894>,
			<14650 16675 20260 14743 14936 15213>,
			<14472 16608 20447 15886 14933 15335>,
			<14566 16685 20023 17927 15078 15287>,
			<14721 16786 19486 20078 15381 15239>,
			<14714 16811 19192 21151 16796 16090>,
			<14547 16822 18834 21897 19527 18181>,
			<14440 16819 18391 22115 20340 19100>,
			<14500 16594 17632 21688 19934 19346>,
			<14592 16334 17045 20902 19358 19464>,
			<14481 16410 16981 19597 18782 19428>,
			<13761 16730 16975 17634 18141 19279>,
			<13117 16868 17016 16970 17550 19095>,
			<12802 16774 17234 17655 16916 18748>,
			<12586 16612 17549 18334 16589 18264>,
			<12557 16283 17984 18284 16707 17353>,
			<12577 15687 18575 18064 16992 16347>,
			<12591 15475 18866 18024 17335 16202>,
			<12620 15643 18993 18531 17822 16427>,
			<12662 15892 19071 19273 18343 16791>,
			<12669 16178 19178 20136 18983 18089>,
			<12664 16618 19330 21105 19515 19605>,
			<12662 16968 19550 21336 19509 19566>,
			<12625 17220 19895 21019 19197 18652>,
			<12570 17516 20106 20642 18898 18215>,
			<12566 18244 20117 20427 18610 18751>,
			<12592 19326 20081 20245 18399 19414>,
			<12614 19585 19800 19998 18428 19550>,
			<12649 18711 18929 19634 18605 19603>,
			<12709 16980 18884 19581 19138 20191>,
			<12898 13772 19235 19766 19261 20538>,
			<13186 13674 17666 19764 18323 19577>,
			<13789 13531 16942 18686 18820 18042>,
			<13782 13491 16501 18047 18648 17652>,
			<13964 13675 16689 17935 18129 17106>,
			<13894 13757 16303 17155 17429 16136>,
			<12739 14003 16280 17670 16621 16308>,
			<11483 14124 16675 19144 18250 16690>,
			<10217 13453 16260 18988 18728 16344>,
			<9289 11878 15022 19819 19716 17749>,
			<8905 9874 15567 21000 23586 23670>,
			<8905 9874 15567 21000 23586 23670>,
			<8905 9874 15567 21000 23586 23670>;
	};

	qcom,pc-temp-y6-lut {
		qcom,lut-col-legend = <(-10) 0 10 25 40 50>;
		qcom,lut-row-legend = <10000 9800 9600 9400 9200 9000>,
			<8800 8600 8400 8200 8000 7800>,
			<7600 7400 7200 7000 6800 6600>,
			<6400 6200 6000 5800 5600 5400>,
			<5200 5000 4800 4600 4400 4200>,
			<4000 3800 3600 3400 3200 3000>,
			<2800 2600 2400 2200 2000 1800>,
			<1600 1400 1200 1000 900 800>,
			<700 600 500 400 300 200>,
			<100 0>;
		qcom,lut-data = <6021 5460 5220 5070 5023 5013>,
			<6030 5470 5224 5072 5024 5013>,
			<6039 5481 5228 5073 5026 5014>,
			<6047 5490 5232 5075 5027 5015>,
			<6053 5498 5236 5078 5029 5016>,
			<6055 5504 5239 5080 5030 5017>,
			<6054 5509 5242 5084 5032 5018>,
			<6051 5513 5246 5087 5034 5020>,
			<6049 5513 5250 5090 5036 5021>,
			<6044 5513 5254 5093 5038 5023>,
			<6040 5513 5258 5096 5040 5024>,
			<6039 5510 5262 5099 5042 5025>,
			<6037 5505 5265 5103 5045 5027>,
			<6034 5501 5264 5108 5047 5029>,
			<6027 5497 5260 5113 5051 5032>,
			<6023 5495 5255 5118 5054 5035>,
			<6022 5492 5248 5123 5059 5038>,
			<6022 5491 5241 5127 5063 5042>,
			<6022 5490 5236 5125 5065 5046>,
			<6023 5490 5232 5114 5067 5051>,
			<6024 5490 5229 5104 5066 5051>,
			<6027 5490 5226 5094 5051 5038>,
			<6030 5491 5224 5086 5037 5025>,
			<6034 5493 5225 5083 5032 5020>,
			<6039 5498 5227 5081 5029 5016>,
			<6045 5503 5229 5081 5029 5016>,
			<6054 5506 5231 5083 5029 5016>,
			<6065 5510 5234 5086 5030 5017>,
			<6080 5515 5237 5088 5032 5018>,
			<6101 5523 5240 5091 5035 5019>,
			<6124 5532 5243 5094 5038 5021>,
			<6148 5546 5247 5098 5042 5024>,
			<6174 5563 5251 5102 5045 5027>,
			<6202 5582 5257 5106 5046 5030>,
			<6233 5605 5265 5110 5047 5031>,
			<6268 5629 5274 5111 5046 5030>,
			<6305 5651 5285 5109 5040 5023>,
			<6347 5676 5296 5107 5037 5019>,
			<6396 5705 5306 5107 5038 5021>,
			<6455 5738 5315 5108 5039 5023>,
			<6518 5765 5324 5109 5040 5026>,
			<6580 5786 5332 5111 5042 5027>,
			<6649 5812 5339 5112 5042 5027>,
			<6733 5849 5343 5112 5039 5023>,
			<6826 5908 5333 5108 5034 5019>,
			<6734 5880 5335 5110 5041 5025>,
			<6860 5960 5358 5117 5046 5032>,
			<7053 6068 5394 5127 5054 5039>,
			<7380 6210 5436 5137 5055 5039>,
			<8250 6422 5487 5140 5048 5031>,
			<9984 6716 5549 5139 5048 5030>,
			<14128 7475 5662 5151 5054 5034>,
			<24997 9730 5880 5175 5064 5041>,
			<51290 15817 6376 5217 5089 5064>,
			<51290 15817 6376 5217 5089 5064>,
			<51290 15817 6376 5217 5089 5064>;
	};

};
